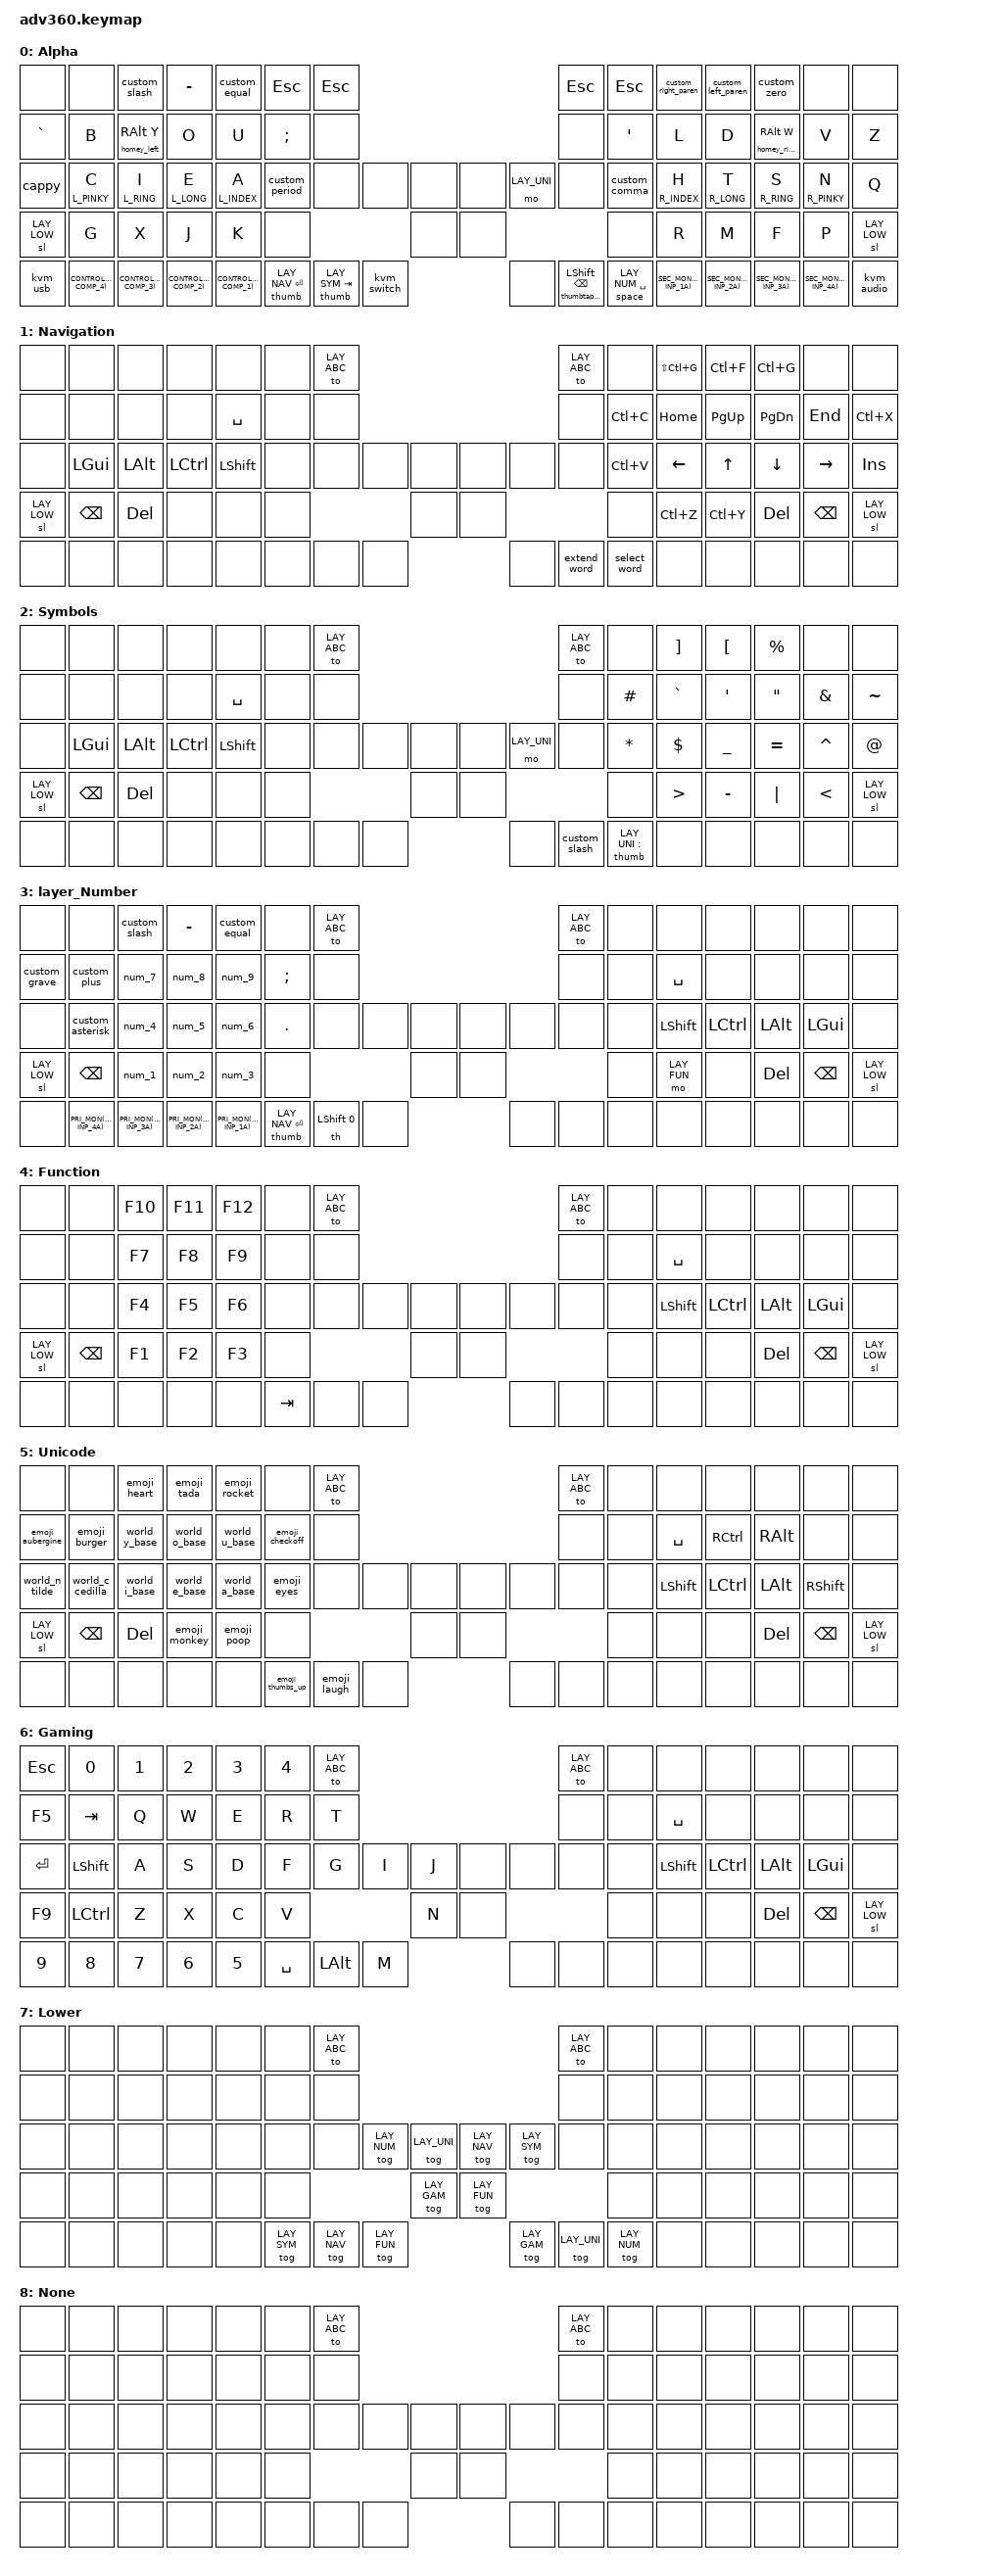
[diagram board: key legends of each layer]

#include <behaviors.dtsi>
#include <dt-bindings/zmk/keys.h>
#include <dt-bindings/zmk/bt.h>
#include <dt-bindings/zmk/rgb.h>
#include <dt-bindings/zmk/stp.h>
#include <dt-bindings/zmk/backlight.h>
#include <dt-bindings/zmk/pointing.h>

/ {
    behaviors {
        #include "version.dtsi"
        // Home Row Mods and Thumb Cluster Mods
        #include "behaviors_home_row_mods.dtsi"
        // Custom "Shifted" behaviors (E.g. Shift + `/` becomes `\`, instead of `?`)
        #include "behaviors_mod_morph_shifted_pairs.dtsi"
        // Overrides for the global ZMK behaviors
        #include "behaviors_global_overrides.dtsi"
        // General macros for common tasks
        #include "macros.dtsi"
        // Word selection and navigation
        #include "macros_words.dtsi"
        // Emoji and Unicode
        #include "macros_world.dtsi"
        // Mouse and cursor movement
        #include "macros_emoji.dtsi"
        // KVM switch and control macros
        #include "macros_kvm.dtsi"
    };

#define CONTROL     KVM_SET_MIRROR_A
#define PRI_MON     KVM_MONITOR_A
#define SEC_MON     KVM_MONITOR_B


#define LAY_DEF 0
#define LAY_ABC 0
#define LAY_NAV 1
#define LAY_SYM 2
#define LAY_NUM 3
#define LAY_FUN 4
#define LAY_UNI 5
#define LAY_GAM 6
#define LAY_LOW 7
#define LAY_NON 8

keymap {
    compatible = "zmk,keymap";
//  Left 1              Left 2              Left 3              Left 4              Left 5              Left 6              Left 7              Left 8              Left 9              Right -9            Right -8            Right -7            Right -6            Right -5            Right -4            Right -3            Right -2            Right -1
        default_layer {
            display-name = "Alpha";
            bindings = <
    &none               &none               &custom_slash       &kp MINUS           &custom_equal       &kp ESC             &kp ESC                                                                                             &kp ESC             &kp ESC             &custom_right_paren &custom_left_paren  &custom_zero        &none               &none
    &kp GRAVE           &kp B               &homey_left RALT Y  &kp O               &kp U               &kp SEMICOLON       &none                                                                                               &none               &kp SINGLE_QUOTE    &kp L               &kp D               &homey_right RALT W &kp V               &kp Z
    &cappy              &L_PINKY C          &L_RING I           &L_LONG E           &L_INDEX A          &custom_period      &none               &none               &none               &none               &mo LAY_UNI         &none               &custom_comma       &R_INDEX H          &R_LONG T           &R_RING S           &R_PINKY N          &kp Q
    &sl LAY_LOW         &kp G               &kp X               &kp J               &kp K               &none                                                       &none               &none                                                       &none               &kp R               &kp M               &kp F               &kp P               &sl LAY_LOW 
    &kvm_usb            CONTROL(KVM_COMP_4) CONTROL(KVM_COMP_3) CONTROL(KVM_COMP_2) CONTROL(KVM_COMP_1)                     &thumb LAY_NAV RET  &thumb LAY_SYM TAB  &kvm_switch         &none               &thumbtaphold LSHFT BSPC    &space LAY_NUM SPC              SEC_MON(KVM_INP_1A) SEC_MON(KVM_INP_2A) SEC_MON(KVM_INP_3A) SEC_MON(KVM_INP_4A) &kvm_audio
            >;
        };

        layer_Navigation { // RIGHT HAND
            display-name = "Navigation";
            bindings = <
    &none               &none               &none               &none               &none               &none               &to LAY_ABC                                                                                         &to LAY_ABC         &none               &kp LS(LC(G))       &kp LC(F)           &kp LC(G)           &none               &none
    &none               &none               &none               &none               &kp SPACE           &none               &none                                                                                               &none               &kp LC(C)           &kp HOME            &kp PG_UP           &kp PG_DN           &kp END             &kp LC(X)
    &none               &kp LEFT_GUI        &kp LEFT_ALT        &kp LCTRL           &kp LEFT_SHIFT      &none               &none               &none               &none               &none              &none                &none               &kp LC(V)           &kp LEFT            &kp UP              &kp DOWN            &kp RIGHT           &kp INSERT
    &sl LAY_LOW         &kp BACKSPACE       &kp DELETE          &none               &none               &none                                                       &none               &none                                                       &none               &kp LC(Z)           &kp LC(Y)           &kp DELETE          &kp BACKSPACE       &sl LAY_LOW 
    &none               &none               &none               &none               &none                                   &none               &none               &none               &none              &extend_word         &select_word                            &none               &none               &none               &none               &none
            >;
        };

        layer_Symbol {  // RIGHT HAND
            display-name = "Symbols";
            bindings = <
    &none               &none               &none               &none               &none               &none               &to LAY_ABC                                                                                         &to LAY_ABC         &none               &kp RIGHT_BRACKET   &kp LEFT_BRACKET    &kp PERCENT         &none               &none
    &none               &none               &none               &none               &kp SPACE           &none               &none                                                                                               &none               &kp HASH            &kp GRAVE           &kp APOSTROPHE      &kp DOUBLE_QUOTES   &kp AMPERSAND       &kp TILDE
    &none               &kp LEFT_GUI        &kp LEFT_ALT        &kp LEFT_CONTROL    &kp LEFT_SHIFT      &none               &none               &none               &none               &none               &mo LAY_UNI         &none               &kp ASTERISK        &kp DOLLAR          &kp UNDERSCORE      &kp EQUAL           &kp CARET           &kp AT_SIGN
    &sl LAY_LOW         &kp BACKSPACE       &kp DELETE          &none               &none               &none                                                       &none               &none                                                       &none               &kp GREATER_THAN    &kp MINUS           &kp PIPE            &kp LESS_THAN       &sl LAY_LOW 
    &none               &none               &none               &none               &none                                   &none               &none               &none               &none               &custom_slash       &thumb LAY_UNI COLON                    &none               &none               &none               &none               &none
            >;
        };

        layer_Number {  // LEFT HAND
            bindings = <
    &none               &none               &custom_slash       &kp MINUS           &custom_equal       &none               &to LAY_ABC                                                                                         &to LAY_ABC         &none               &none               &none               &none               &none               &none
    &custom_grave       &custom_plus        &num_7              &num_8              &num_9              &kp SEMI            &none                                                                                               &none               &none               &kp SPACE           &none               &none               &none               &none
    &none               &custom_asterisk    &num_4              &num_5              &num_6              &kp PERIOD          &none               &none               &none               &none               &none               &none               &none               &kp LEFT_SHIFT      &kp LCTRL           &kp LEFT_ALT        &kp LEFT_GUI        &none
    &sl LAY_LOW         &kp BACKSPACE       &num_1              &num_2              &num_3              &none                                                       &none               &none                                                       &none               &mo LAY_FUN         &none               &kp DELETE          &kp BACKSPACE       &sl LAY_LOW 
    &none               PRI_MON(KVM_INP_4A) PRI_MON(KVM_INP_3A) PRI_MON(KVM_INP_2A) PRI_MON(KVM_INP_1A)                     &thumb LAY_NAV RET  &th LSHFT N0        &none               &none               &none               &none                                   &none               &none               &none               &none               &none
            >;
        };

        layer_Function { // RIGHT HAND
            display-name = "Function";
            bindings = <
    &none               &none               &kp F10             &kp F11             &kp F12             &none               &to LAY_ABC                                                                                         &to LAY_ABC         &none               &none               &none               &none               &none               &none
    &none               &none               &kp F7              &kp F8              &kp F9              &none               &none                                                                                               &none               &none               &kp SPACE           &none               &none               &none               &none
    &none               &none               &kp F4              &kp F5              &kp F6              &none               &none               &none               &none               &none               &none               &none               &none               &kp LSHFT           &kp LCTRL           &kp LEFT_ALT        &kp LEFT_GUI        &none
    &sl LAY_LOW         &kp BACKSPACE       &kp F1              &kp F2              &kp F3              &none                                                       &none               &none                                                       &none               &none               &none               &kp DELETE          &kp BACKSPACE       &sl LAY_LOW 
    &none               &none               &none               &none               &none                                   &kp TAB             &none               &none               &none               &none               &none                                   &none               &none               &none               &none               &none
            >;
        };

        layer_Unicode { // LEFT HAND
            display-name = "Unicode";
            bindings = <
    &none               &none               &emoji_heart        &emoji_tada         &emoji_rocket       &none               &to LAY_ABC                                                                                         &to LAY_ABC         &none               &none               &none               &none               &none               &none
    &emoji_aubergine    &emoji_burger       &world_y_base       &world_o_base       &world_u_base       &emoji_checkoff     &none                                                                                               &none               &none               &kp SPACE           &kp RIGHT_CONTROL   &kp RALT            &none               &none
    &world_n_tilde      &world_c_cedilla    &world_i_base       &world_e_base       &world_a_base       &emoji_eyes         &none               &none               &none               &none               &none               &none               &none               &kp LSHFT           &kp LEFT_CONTROL    &kp LEFT_ALT        &kp RSHIFT          &none
    &sl LAY_LOW         &kp BACKSPACE       &kp DELETE          &emoji_monkey       &emoji_poop         &none                                                       &none               &none                                                       &none               &none               &none               &kp DELETE          &kp BACKSPACE       &sl LAY_LOW 
    &none               &none               &none               &none               &none                                   &emoji_thumbs_up    &emoji_laugh        &none               &none               &none               &none                                   &none               &none               &none               &none               &none
            >; 
        };

        layer_Gaming {  // LEFT HAND
            display-name = "Gaming";
            bindings = <
    &kp ESC             &kp NUMBER_0        &kp NUMBER_1        &kp NUMBER_2        &kp NUMBER_3        &kp NUMBER_4        &to LAY_ABC                                                                                         &to LAY_ABC         &none               &none               &none               &none               &none               &none
    &kp F5              &kp TAB             &kp Q               &kp W               &kp E               &kp R               &kp T                                                                                               &none               &none               &kp SPACE           &none               &none               &none               &none
    &kp ENTER           &kp LEFT_SHIFT      &kp A               &kp S               &kp D               &kp F               &kp G               &kp I               &kp J               &none               &none               &none               &none               &kp LEFT_SHIFT      &kp LCTRL           &kp LEFT_ALT        &kp LEFT_GUI        &none
    &kp F9              &kp LCTRL           &kp Z               &kp X               &kp C               &kp V                                                       &kp N               &none                                                       &none               &none               &none               &kp DELETE          &kp BACKSPACE       &sl LAY_LOW 
    &kp NUMBER_9        &kp NUMBER_8        &kp NUMBER_7        &kp NUMBER_6        &kp NUMBER_5                            &kp SPACE           &kp LEFT_ALT        &kp M               &none               &none               &none                                   &none               &none               &none               &none               &none
            >;
        };

        layer_lower {
            display-name = "Lower";
            bindings = <
    &none               &none               &none               &none               &none               &none               &to LAY_ABC                                                                                         &to LAY_ABC         &none               &none               &none               &none               &none               &none
    &none               &none               &none               &none               &none               &none               &none                                                                                               &none               &none               &none               &none               &none               &none               &none
    &none               &none               &none               &none               &none               &none               &none               &tog LAY_NUM        &tog LAY_UNI       &tog LAY_NAV         &tog LAY_SYM        &none               &none               &none               &none               &none               &none               &none
    &none               &none               &none               &none               &none               &none                                                       &tog LAY_GAM       &tog LAY_FUN                                                 &none               &none               &none               &none               &none               &none
    &none               &none               &none               &none               &none                                   &tog LAY_SYM        &tog LAY_NAV        &tog LAY_FUN       &tog LAY_GAM         &tog LAY_UNI        &tog LAY_NUM                            &none               &none               &none               &none               &none
            >;
        };

        layer_none {
            display-name = "None";
            bindings = <
    &none               &none               &none               &none               &none               &none               &to LAY_ABC                                                                                         &to LAY_ABC         &none               &none               &none               &none               &none               &none
    &none               &none               &none               &none               &none               &none               &none                                                                                               &none               &none               &none               &none               &none               &none               &none
    &none               &none               &none               &none               &none               &none               &none               &none               &none              &none                &none               &none               &none               &none               &none               &none               &none               &none
    &none               &none               &none               &none               &none               &none                                                       &none              &none                                                        &none               &none               &none               &none               &none               &none 
    &none               &none               &none               &none               &none                                   &none               &none               &none              &none                &none               &none                                   &none               &none               &none               &none               &none
            >;
        };
    };

    #include "hacks_emoji.dtsi"
    #include "hacks_mouse.dtsi"

};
